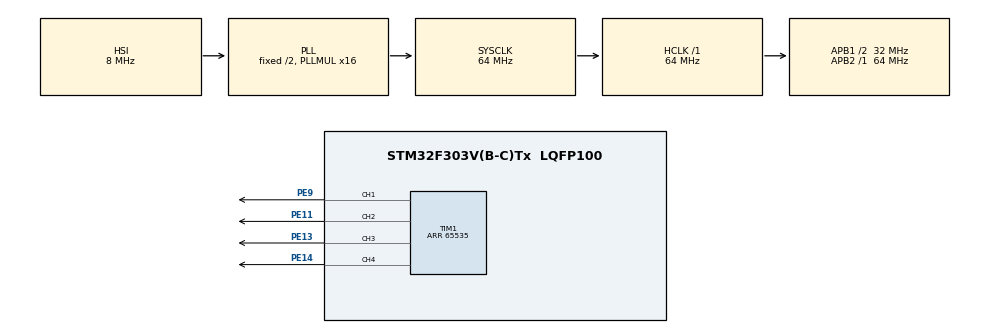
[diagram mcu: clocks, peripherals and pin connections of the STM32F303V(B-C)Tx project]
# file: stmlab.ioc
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Mcu.Family=STM32F3
Mcu.Name=STM32F303V(B-C)Tx
Mcu.Package=LQFP100
NVIC.PriorityGroup=NVIC_PRIORITYGROUP_4
NVIC.TIM1_CC_IRQn=true\:0\:0\:false\:false\:true\:true\:true
PE11.GPIO_Speed=GPIO_SPEED_FREQ_HIGH
PE11.Signal=S_TIM1_CH2
PE13.GPIO_Speed=GPIO_SPEED_FREQ_HIGH
PE13.Signal=S_TIM1_CH3
PE14.GPIO_Speed=GPIO_SPEED_FREQ_HIGH
PE14.Signal=S_TIM1_CH4
PE9.GPIO_Speed=GPIO_SPEED_FREQ_HIGH
PE9.Signal=S_TIM1_CH1
PF0-OSC_IN.Mode=HSE-External-Oscillator
PF0-OSC_IN.Signal=RCC_OSC_IN
PF1-OSC_OUT.Mode=HSE-External-Oscillator
PF1-OSC_OUT.Signal=RCC_OSC_OUT
ProjectManager.HeapSize=0x200
ProjectManager.StackSize=0x400
ProjectManager.TargetToolchain=SW4STM32
RCC.AHBFreq_Value=64000000
RCC.APB1CLKDivider=RCC_HCLK_DIV2
RCC.APB1Freq_Value=32000000
RCC.APB1TimFreq_Value=64000000
RCC.APB2Freq_Value=64000000
RCC.APB2TimFreq_Value=64000000
RCC.CortexFreq_Value=64000000
RCC.HCLKFreq_Value=64000000
RCC.HSE_VALUE=8000000
RCC.HSI_VALUE=8000000
RCC.PLLMUL=RCC_PLL_MUL16
RCC.SYSCLKFreq_VALUE=64000000
RCC.SYSCLKSourceVirtual=RCC_SYSCLKSOURCE_PLLCLK
RCC.USBFreq_Value=64000000
SH.S_TIM1_CH1.0=TIM1_CH1,PWM Generation1 CH1
SH.S_TIM1_CH2.0=TIM1_CH2,PWM Generation2 CH2
SH.S_TIM1_CH3.0=TIM1_CH3,PWM Generation3 CH3
SH.S_TIM1_CH4.0=TIM1_CH4,PWM Generation4 CH4
TIM1.Channel-PWM\ Generation1\ CH1=TIM_CHANNEL_1
TIM1.Channel-PWM\ Generation2\ CH2=TIM_CHANNEL_2
TIM1.Channel-PWM\ Generation3\ CH3=TIM_CHANNEL_3
TIM1.Channel-PWM\ Generation4\ CH4=TIM_CHANNEL_4
TIM1.OCFastMode_PWM-PWM\ Generation1\ CH1=TIM_OCFAST_DISABLE
TIM1.OCFastMode_PWM-PWM\ Generation2\ CH2=TIM_OCFAST_DISABLE
TIM1.OCFastMode_PWM-PWM\ Generation3\ CH3=TIM_OCFAST_DISABLE
TIM1.OCFastMode_PWM-PWM\ Generation4\ CH4=TIM_OCFAST_DISABLE
TIM1.Period=65535
VP_TIM1_VS_ClockSourceINT.Mode=Internal
board=custom

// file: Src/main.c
/* USER CODE BEGIN Header */
/**
  ******************************************************************************
  * @file           : main.c
  * @brief          : Main program body
  ******************************************************************************
  * @attention
  *
  * <h2><center>&copy; Copyright (c) 2019 STMicroelectronics.
  * All rights reserved.</center></h2>
  *
  * This software component is licensed by ST under BSD 3-Clause license,
  * the "License"; You may not use this file except in compliance with the
  * License. You may obtain a copy of the License at:
  *                        opensource.org/licenses/BSD-3-Clause
  *
  ******************************************************************************
  */
/* USER CODE END Header */

#include "main.h"
#include "tim.h"
#include "gpio.h"

void SystemClock_Config(void);

int main(void)
{

  /* MCU Configuration--------------------------------------------------------*/

  /* Reset of all peripherals, Initializes the Flash interface and the Systick. */
  HAL_Init();

  /* Configure the system clock */
  SystemClock_Config();

  /* Initialize all configured peripherals */
  MX_GPIO_Init();
  MX_TIM1_Init();

  /* Infinite loop */
  /* USER CODE BEGIN WHILE */

  /* USER CODE BEGIN WHILE */
//    int pressed = 15;
//    while (1)
//    {
//     if ( HAL_GPIO_ReadPin(UButton_GPIO_Port, UButton_Pin) )
//     {
//      ++pressed;
//      HAL_Delay(50); //<========
//      while( HAL_GPIO_ReadPin(UButton_GPIO_Port, UButton_Pin) )
//      {}
//      HAL_Delay(50); //<========
//     }
//    GPIOE->ODR &= ~(0xFF << 8);
//	GPIOE->ODR |= (pressed & 0xFF) << 8;

    /* USER CODE END WHILE */

    /* USER CODE BEGIN 3 */
  HAL_TIM_PWM_Start(&htim1, TIM_CHANNEL_1);
  HAL_TIM_PWM_Start(&htim1, TIM_CHANNEL_2);
  HAL_TIM_PWM_Start(&htim1, TIM_CHANNEL_3);
  HAL_TIM_PWM_Start(&htim1, TIM_CHANNEL_4);
  uint32_t i, d;
  d = 1;
  while (1)
    {
     for(i = 0; i <= 65535; i++) {
    	 TIM4->CCR2 = 32000;
    	 HAL_Delay(d);
     }
     for(i = 65535; i > 0; i--) {
         	 TIM4->CCR2 = 32000;
		 HAL_Delay(d);
          }
    }

//    }
  /* USER CODE END 3 */
}

void SystemClock_Config(void)
{
  RCC_OscInitTypeDef RCC_OscInitStruct = {0};
  RCC_ClkInitTypeDef RCC_ClkInitStruct = {0};
  RCC_PeriphCLKInitTypeDef PeriphClkInit = {0};

  /** Initializes the CPU, AHB and APB busses clocks
  */
  RCC_OscInitStruct.OscillatorType = RCC_OSCILLATORTYPE_HSI;
  RCC_OscInitStruct.HSIState = RCC_HSI_ON;
  RCC_OscInitStruct.HSICalibrationValue = RCC_HSICALIBRATION_DEFAULT;
  RCC_OscInitStruct.PLL.PLLState = RCC_PLL_ON;
  RCC_OscInitStruct.PLL.PLLSource = RCC_PLLSOURCE_HSI;
  RCC_OscInitStruct.PLL.PLLMUL = RCC_PLL_MUL16;
  if (HAL_RCC_OscConfig(&RCC_OscInitStruct) != HAL_OK)
  {
    Error_Handler();
  }
  /** Initializes the CPU, AHB and APB busses clocks
  */
  RCC_ClkInitStruct.ClockType = RCC_CLOCKTYPE_HCLK|RCC_CLOCKTYPE_SYSCLK
                              |RCC_CLOCKTYPE_PCLK1|RCC_CLOCKTYPE_PCLK2;
  RCC_ClkInitStruct.SYSCLKSource = RCC_SYSCLKSOURCE_PLLCLK;
  RCC_ClkInitStruct.AHBCLKDivider = RCC_SYSCLK_DIV1;
  RCC_ClkInitStruct.APB1CLKDivider = RCC_HCLK_DIV2;
  RCC_ClkInitStruct.APB2CLKDivider = RCC_HCLK_DIV1;

  if (HAL_RCC_ClockConfig(&RCC_ClkInitStruct, FLASH_LATENCY_2) != HAL_OK)
  {
    Error_Handler();
  }
  PeriphClkInit.PeriphClockSelection = RCC_PERIPHCLK_TIM1;
  PeriphClkInit.Tim1ClockSelection = RCC_TIM1CLK_HCLK;
  if (HAL_RCCEx_PeriphCLKConfig(&PeriphClkInit) != HAL_OK)
  {
    Error_Handler();
  }
}

void Error_Handler(void)
{
}

/************************ (C) COPYRIGHT STMicroelectronics *****END OF FILE****/
